# STM32MP23_CM33 register map
File version: 1.2
CPU: CM33 r0p1, little endian, MPU, FPU, vendor SysTick, 8 interrupt priority bits
Registers are 32-bit, read-write, reset 0x0 unless marked. A register's access mark holds for its fields unless they carry their own. Offsets are from the block's base; [hi:lo] are bit positions; 'fields as' and 'values as' point back to an identical list.

## DTS — DTS address block description
Base 0x44070000
Same registers: DTS_S 0x54070000
0x10 DTS_PVTREG_LOCKR — DTS PVT register lock register
  [31:0] LOCK — PVT software lock register Any write to this register locks all DTS registers except for the PVT common registers. Once locked, the DTS registers are read-only. The software lock can be removed by writing 0x1ACCE551.
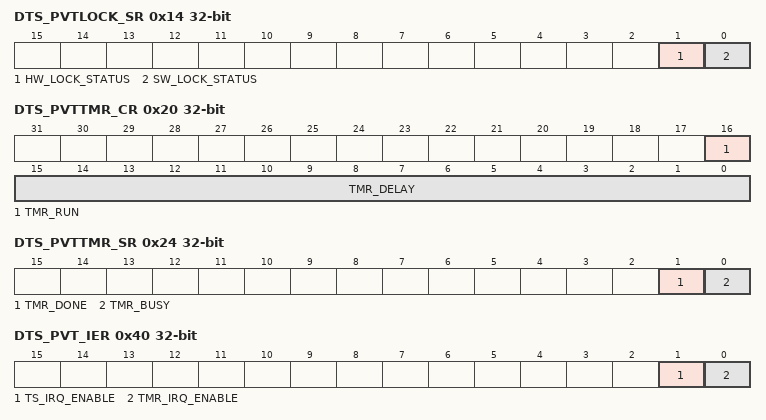
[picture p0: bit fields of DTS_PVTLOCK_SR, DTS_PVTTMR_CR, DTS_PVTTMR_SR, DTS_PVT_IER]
0x14 DTS_PVTLOCK_SR ro — DTS PVT lock status register
  [1] HW_LOCK_STATUS — Hardware lock input status This bit indicates the status of the hardware lock input to the PVT controller.
  [0] SW_LOCK_STATUS — Software lock input status This bit indicates the current state of the lock register.
0x20 DTS_PVTTMR_CR — DTS PVT timer control register
  [16] TMR_RUN — Timer count enable bit This bit enables the timer count function.
  [15:0] TMR_DELAY — Timer delay This bit field can be used to configure the timer delay.
0x24 DTS_PVTTMR_SR ro — DTS PVT timer status register
  [1] TMR_DONE — Counter delay expiration flag This bit is set when the counter delay has expired.
  [0] TMR_BUSY — Counter busy flag This bit is set while the counter is active.
0x40 DTS_PVT_IER — DTS PVT IRQ enable register
  [1] TS_IRQ_ENABLE — TS IRQ source enable bit Set this bit to enable the TS IRQ to the processor.
  [0] TMR_IRQ_ENABLE — Timer IRQ source enable bit Set this bit to enable the timer IRQ to the processor.
0x50 DTS_PVTIRQTRMASKR — DTS PVT IRQ timer mask register
  [0] TMR_IRQ_MASK — Timer IRQ source mask bit Set this bit to mask the timer IRQ to the processor.
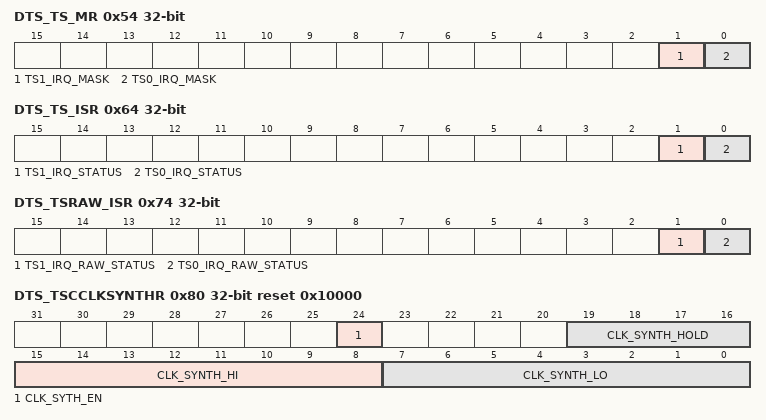
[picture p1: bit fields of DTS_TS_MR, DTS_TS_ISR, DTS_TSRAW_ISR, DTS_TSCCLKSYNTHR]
0x54 DTS_TS_MR — DTS PVT IRQ TS mask register
  [1] TS1_IRQ_MASK — TS1 IRQ source mask bit Set this bit to mask TS1 IRQ to the processor.
  [0] TS0_IRQ_MASK — TS0 IRQ source mask bit Set this bit to mask TS0 IRQ to the processor.
0x60 DTS_PVTTR_SR ro — DTS PVT IRQ timer status register
  [0] TMR_IRQ_STATUS — Timer IRQ status bit after masking This bit reflects the timer IRQ status after the mask has been applied.
0x64 DTS_TS_ISR ro — DTS PVT IRQ TS status register
  [1] TS1_IRQ_STATUS — TS1 IRQ status bit after masking This bit reflects the timer IRQ status after the mask has been applied. Note: The bit is set when the corresponding TS block has issued an IRQ interrupt to the processor.
  [0] TS0_IRQ_STATUS — TS0 IRQ status bit after masking This bit reflects the timer IRQ status after the mask has been applied. Note: The bit is set when the corresponding TS block has issued an IRQ interrupt to the processor.
0x70 DTS_PVTTMRRAW_ISR ro — DTS PVT IRQ timer raw status register
  [0] TMR_IRQ_RAW_STATUS — TMR IRQ status bit before masking This bit reflects the timer IRQ status before the mask is applied.
0x74 DTS_TSRAW_ISR ro — DTS PVT IRQ TS raw status register
  [1] TS1_IRQ_RAW_STATUS — TS1 IRQ status bit before masking This bit reflects the timer IRQ status before the mask is applied.
  [0] TS0_IRQ_RAW_STATUS — TS0 IRQ status bit before masking This bit reflects the timer IRQ status before the mask is applied.
0x80 DTS_TSCCLKSYNTHR reset 0x10000 — DTS TSC clock synthesizer register
  [24] CLK_SYTH_EN — Synthesized clk_ts enable bit
    0=Disabled; 1=Enabled
  [19:16] CLK_SYNTH_HOLD — SDA master-to-SDA slave output hold delay/SDA slave-to-SDA master input setup delay The delay is counted from the riding edge of clk_ts. It is expressed in units of dts_pclk cycles. The default value is 0b0001.
  [15:8] CLK_SYNTH_HI — Synthesized clk_ts high period This is a zero-Indexed value expressed in units of dts_pclk cycles.
  [7:0] CLK_SYNTH_LO — Synthesized clk_ts low period This is a zero-Indexed value expressed in units of dts_pclk cycles.
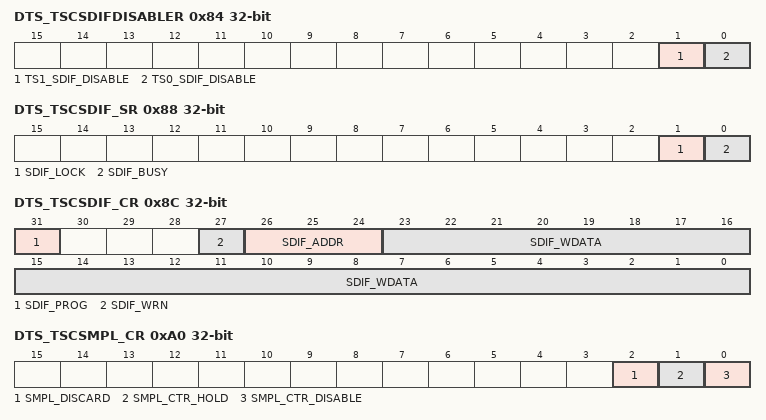
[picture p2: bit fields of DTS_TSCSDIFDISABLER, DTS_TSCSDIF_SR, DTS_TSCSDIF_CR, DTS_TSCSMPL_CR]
0x84 DTS_TSCSDIFDISABLER — DTS TSC SDIF interface disable register
  [1] TS1_SDIF_DISABLE — TS1 serial data interface (SDIF) disable bit When this bit is asserted, it completely disables TS1 instance by forcing TS1 clock and reset low.
    0=Enabled; 1=Disabled
  [0] TS0_SDIF_DISABLE — TS0 serial data interface (SDIF) disable bit When this bit is asserted, it completely disables the selected TS0 instance by forcing TS0 clock and reset low.
    0=Enabled; 1=Disabled
0x88 DTS_TSCSDIF_SR ro — DTS TSC SDIF status register
  [1] SDIF_LOCK — SDIF locked flag This bit is set when the slave automatic mode is requested, to indicate that the serial data interface (SDIF) is now a write-only interface (see Section: SDA controller operation). In slave automatic mode, the data register (SDATS_DR) is automatically updated within the PVT controller whenever new TS data become available
    0=Unlocked; 1=Locked
  [0] SDIF_BUSY — SDIF busy flag When asserted, this bit indicates either that the serial data interface (SDIF) is busy and any SDIF programming requests are ignored, or the clock synthesizer/disable SDIF state is being updated.
    0=SDIF not busy/no clock synthesizer/disable SDIF state update ongoing; 1=SDIF busy/clock synthesizer/disable SDIF state update ongoing
0x8C DTS_TSCSDIF_CR — DTS TSC SDIF register
  [31] SDIF_PROG wo — Serial interface program request This self-clearing bit is ignored if the SDIF_BUSY or the SDIF_LOCK flag is set, and the request is a read request (SDIF_WRN=0).
    0=No SDIF program request; 1=SDIF program requested
  [27] SDIF_WRN — Serial interface write/no read control bit
    0=SDIF read; 1=SDIF write
  [26:24] SDIF_ADDR — Serial interface register address This bit field contains the address of the target SDIF register, SDIF_ADDR[2:0].
  [23:0] SDIF_WDATA — Serial interface write data This bit field contains the write data SDIF_DATA[23:0].
0x90 DTS_TSCSDIFHALTR wo — DTS TSC SDIF halt register
  [0] SDIF_STOP — Serial data interface (SDIF) stop This self-clearing bit immediately stops all SDIF programming activity in the unlikely event of it becoming locked. It must not be required during normal operation.
    0=Not stopped; 1=Stopped
0x94 DTS_TSCSDIF_CFGR — DTS TSC SDIF control register
  [1:0] SDIF_INHIBIT — Serial data interface (SDIF) programming inhibit When asserted, this bit inhibits the serial programming of the selected TS instance(s). The inhibition must be applied before SDIF programming begins.
    0=No Inhibition; 1=TS0 inhibited/TS1 serial programming activated (SPA); 2=TS1 inhibited/TS0 serial programming activated (SPA); 3=TS1 and TS0 inhibited
0xA0 DTS_TSCSMPL_CR — DTS TSC sample control register
  [2] SMPL_DISCARD — Sample discard bit This feature can be used to temporarily discard received data samples. When this bit is set, data recovery is disabled but the external TS may continue running.
    0=Data samples not discarded; 1=Data samples discarded
  [1] SMPL_CTR_HOLD — Sample counter hold bit When this bit is asserted, the sample counter is prevented from rolling over when the maximum sample count is reached.
    0=Counter not on hold; 1=Counter on hold
  [0] SMPL_CTR_DISABLE — Sample counter disable bit
    0=Sample counter enabled; 1=Sample counter disabled
0xA4 DTS_TSCSDIFSMPLCLRR wo — DTS TSC sample clear register
  [0] SMPL_CNTER_CLEAR — Sample counter clear bit The sample counter value is set to zero when this self-clearing bit is programmed to 1.
    0=Counter value not cleared; 1=Counter value cleared
0xA8 DTS_TSCSMPLCNTR ro — DTS TSC sample count register
  [15:0] SMPL_COUNT — Sample counter The 16-bit counter increments each time a new data sample is available. The counter is cleared by writing 1 to DTS_TSCSDIFSMPLCLRR. The sample counter overflow operation is determined by SMPL_CTR_HOLD.
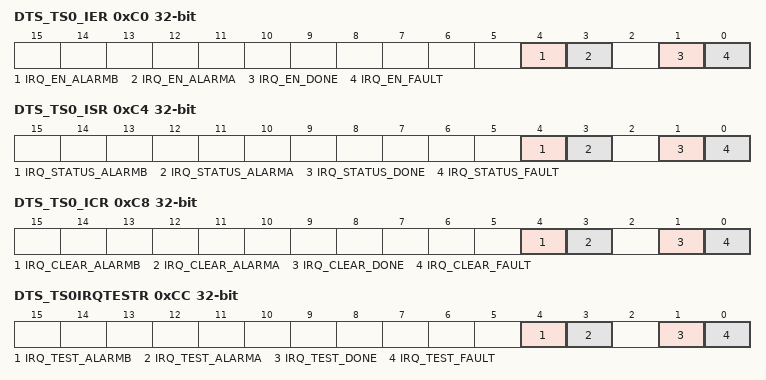
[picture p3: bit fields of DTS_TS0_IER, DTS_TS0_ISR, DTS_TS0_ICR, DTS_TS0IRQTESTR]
0xC0 DTS_TS0_IER — DTS TS0 IRQ enable register
  [4] IRQ_EN_ALARMB — Alarm B IRQ enable bit
  [3] IRQ_EN_ALARMA — Alarm A IRQ enable bit
  [1] IRQ_EN_DONE — Sample done IRQ enable bit
  [0] IRQ_EN_FAULT — Fault IRQ enable bit
0xC4 DTS_TS0_ISR ro — DTS TS0 IRQ status register
  [4] IRQ_STATUS_ALARMB — Alarm B IRQ status bit
  [3] IRQ_STATUS_ALARMA — Alarm A IRQ status bit
  [1] IRQ_STATUS_DONE — Sample done IRQ status bit
  [0] IRQ_STATUS_FAULT — Fault IRQ status bit
0xC8 DTS_TS0_ICR wo — DTS TS0 IRQ clear register
  [4] IRQ_CLEAR_ALARMB — Alarm B IRQ clear bit
  [3] IRQ_CLEAR_ALARMA — Alarm A IRQ clear bit
  [1] IRQ_CLEAR_DONE — Sample done IRQ clear bit
  [0] IRQ_CLEAR_FAULT — Fault IRQ clear bit
0xCC DTS_TS0IRQTESTR — DTS TS0 IRQ test register
  [4] IRQ_TEST_ALARMB — Alarm B IRQ test bit
  [3] IRQ_TEST_ALARMA — Alarm A IRQ test bit
  [1] IRQ_TEST_DONE — Sample done IRQ test bit
  [0] IRQ_TEST_FAULT — Fault IRQ test bit
0xD0 DTS_TS0SDIFRDATAR ro — DTS TS0 SDIF RDATA register
  [23:0] SDIF_RDATA — SDIF read data
0xD4 DTS_TS0SDIFDONER ro — DTS TS0 SDIF done register
  [0] SDIF_SMPL_DONE — Sample done flag The sample done flag is asserted when a new data sample is available. The sample done flag is automatically cleared when the associated data register is read.
    0=No new data sample available; 1=New data sample available
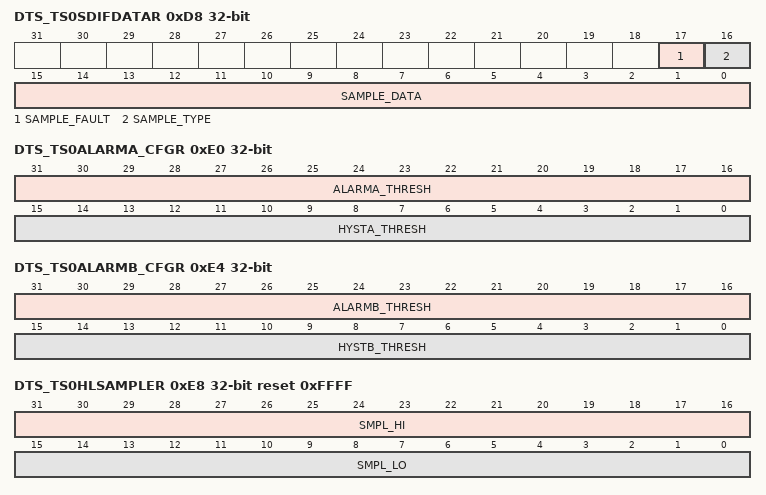
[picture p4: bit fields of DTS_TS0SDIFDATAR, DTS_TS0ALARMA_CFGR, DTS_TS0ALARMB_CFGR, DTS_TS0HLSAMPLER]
0xD8 DTS_TS0SDIFDATAR ro — DTS TS0 SDIF data register
  [17] SAMPLE_FAULT — Sample fault This bit is set to indicate that the TS block has signaled a fault. The sample data must be discarded.
  [16] SAMPLE_TYPE — TS sample type The TS_TYPE flag is updated when new data are received.
    0=Indicates valid data; 1=Indicates either analog access, signature select or fault debug mode
  [15:0] SAMPLE_DATA — Sample data. Reading this register clears the state of the SDIF_SMPL_DONE flag in DTS_TSnSDIFDONER register.
0xE0 DTS_TS0ALARMA_CFGR — DTS TS0 alarm A configuration register
  [31:16] ALARMA_THRESH — Alarm A threshold
  [15:0] HYSTA_THRESH — Alarm A hysteresis threshold
0xE4 DTS_TS0ALARMB_CFGR — DTS TS0 alarm B configuration register
  [31:16] ALARMB_THRESH — Alarm B threshold
  [15:0] HYSTB_THRESH — Alarm B hysteresis threshold
0xE8 DTS_TS0HLSAMPLER ro reset 0xFFFF — DTS TS0 high/low sample register
  [31:16] SMPL_HI — Highest valid data sample value received
  [15:0] SMPL_LO — Lowest valid data sample value received
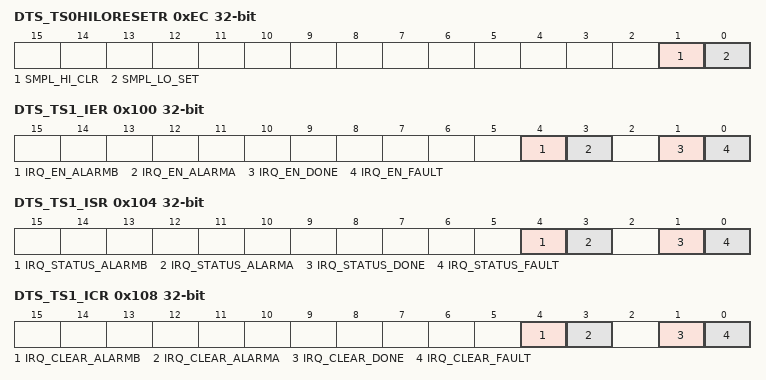
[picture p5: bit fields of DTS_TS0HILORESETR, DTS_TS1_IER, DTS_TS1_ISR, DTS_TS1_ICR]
0xEC DTS_TS0HILORESETR wo — DTS TS0 high/low reset register
  [1] SMPL_HI_CLR — Sample high clear 0 All the bits of the stored sample high value are initialized to 0 when written.
  [0] SMPL_LO_SET — Sample Low Set All the bits of the stored sample low value are initialized to 1 when written.
0x100 DTS_TS1_IER — DTS TS1 IRQ enable register
  fields as DTS_TS0_IER
0x104 DTS_TS1_ISR ro — DTS TS1 IRQ status register
  fields as DTS_TS0_ISR
0x108 DTS_TS1_ICR wo — DTS TS1 IRQ clear register
  fields as DTS_TS0_ICR
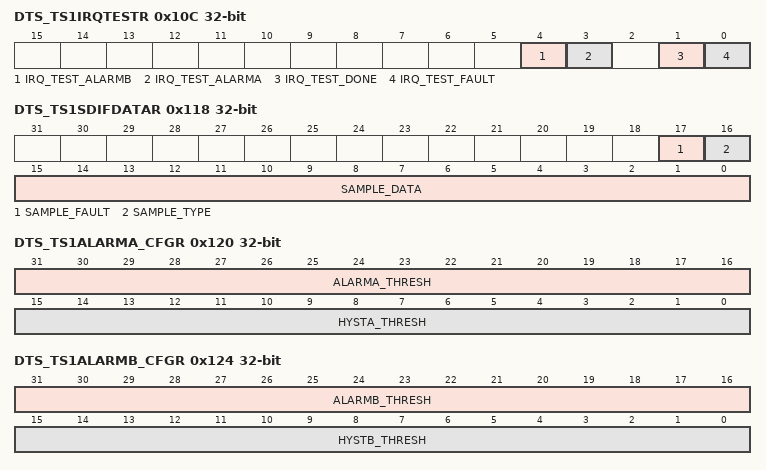
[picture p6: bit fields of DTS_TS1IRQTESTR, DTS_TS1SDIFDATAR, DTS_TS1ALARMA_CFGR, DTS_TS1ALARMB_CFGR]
0x10C DTS_TS1IRQTESTR — DTS TS1 IRQ test register
  fields as DTS_TS0IRQTESTR
0x110 DTS_TS1SDIFRDATAR ro — DTS TS1 SDIF RDATA register
  [23:0] SDIF_RDATA — SDIF read data
0x114 DTS_TS1SDIFDONER ro — DTS TS1 SDIF done register
  fields as DTS_TS0SDIFDONER
0x118 DTS_TS1SDIFDATAR ro — DTS TS1 SDIF data register
  fields as DTS_TS0SDIFDATAR
0x120 DTS_TS1ALARMA_CFGR — DTS TS1 alarm A configuration register
  fields as DTS_TS0ALARMA_CFGR
0x124 DTS_TS1ALARMB_CFGR — DTS TS1 alarm B configuration register
  fields as DTS_TS0ALARMB_CFGR
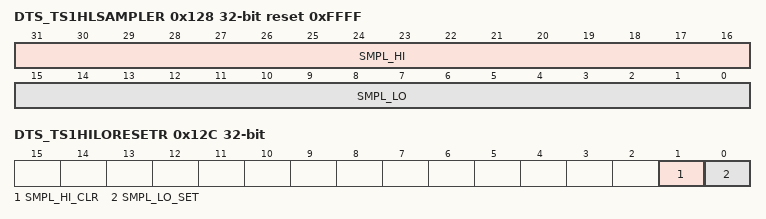
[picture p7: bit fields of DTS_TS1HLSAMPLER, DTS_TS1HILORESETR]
0x128 DTS_TS1HLSAMPLER ro reset 0xFFFF — DTS TS1 high/low sample register
  fields as DTS_TS0HLSAMPLER
0x12C DTS_TS1HILORESETR wo — DTS TS1 high/low reset register
  fields as DTS_TS0HILORESETR
